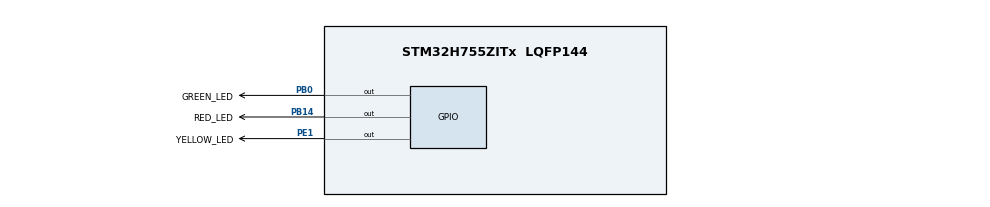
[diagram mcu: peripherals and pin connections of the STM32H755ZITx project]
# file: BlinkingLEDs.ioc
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CortexM4.IPs=BDMA,CORTEX_M4\:I,DEBUG,DMA,FATFS_M4\:I,FREERTOS_M4\:I,GPIO,IWDG2\:I,MDMA,NVIC2\:I,OPENAMP_M4\:I,PDM2PCM_M4\:I,PWR,RCC,RESMGR_UTILITY,SYS_M4\:I,USB_DEVICE_M4\:I,USB_HOST_M4\:I,VREFBUF,WWDG2\:I
CortexM4.Pins=PE1
CortexM7.IPs=BDMA\:I,CORTEX_M7\:I,DEBUG\:I,DMA\:I,FATFS_M7\:I,FREERTOS_M7\:I,GPIO\:I,IWDG1\:I,MDMA\:I,NVIC1\:I,OPENAMP_M7\:I,PDM2PCM_M7\:I,PWR\:I,RCC\:I,RESMGR_UTILITY\:I,SYS\:I,USB_DEVICE_M7\:I,USB_HOST_M7\:I,VREFBUF\:I,WWDG1\:I
CortexM7.Pins=PB0,PB14
Mcu.Family=STM32H7
Mcu.Name=STM32H755ZITx
Mcu.Package=LQFP144
NVIC1.PriorityGroup=NVIC_PRIORITYGROUP_4
NVIC2.PriorityGroup=NVIC_PRIORITYGROUP_4
PA13\ (JTMS/SWDIO).Mode=Serial_Wire
PA13\ (JTMS/SWDIO).PinAttribute=CortexM7
PA13\ (JTMS/SWDIO).Signal=DEBUG_JTMS-SWDIO
PA14\ (JTCK/SWCLK).Mode=Serial_Wire
PA14\ (JTCK/SWCLK).PinAttribute=CortexM7
PA14\ (JTCK/SWCLK).Signal=DEBUG_JTCK-SWCLK
PB0.GPIO_Label=GREEN_LED
PB0.PinAttribute=CortexM7
PB0.Signal=GPIO_Output
PB14.GPIO_Label=RED_LED
PB14.PinAttribute=CortexM7
PB14.Signal=GPIO_Output
PE1.GPIO_Label=YELLOW_LED
PE1.PinAttribute=CortexM4
PE1.Signal=GPIO_Output
ProjectManager.HeapSize=M4-0x200,M7-0x200
ProjectManager.StackSize=M4-0x400,M7-0x400
ProjectManager.TargetToolchain=STM32CubeIDE
RCC.ADCFreq_Value=129000000
RCC.APB1Freq_Value=120000000
RCC.APB2Freq_Value=120000000
RCC.APB3Freq_Value=120000000
RCC.APB4Freq_Value=120000000
RCC.CortexFreq_Value=480000000
RCC.D1PPRE=RCC_APB3_DIV2
RCC.D2PPRE1=RCC_APB1_DIV2
RCC.D2PPRE2=RCC_APB2_DIV2
RCC.D3PPRE=RCC_APB4_DIV2
RCC.DIVM1=4
RCC.DIVN1=60
RCC.HCLKFreq_Value=240000000
RCC.HPRE=RCC_HCLK_DIV2
RCC.PLL2FRACN=0
RCC.PLL3FRACN=0
RCC.PLLFRACN=0
RCC.PWR_Regulator_Voltage_Scale=PWR_REGULATOR_VOLTAGE_SCALE0
RCC.SYSCLKFreq_VALUE=480000000
RCC.SYSCLKSource=RCC_SYSCLKSOURCE_PLLCLK
RCC.USBFreq_Value=480000000
SYS.userName=SYS_M7
VP_SYS_M4_VS_Systick.Mode=SysTick
board=custom

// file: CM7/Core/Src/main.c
/* USER CODE BEGIN Header */
/**
 ******************************************************************************
 * @file           : main.c
 * @brief          : Main program body
 ******************************************************************************
 * @attention
 *
 * Copyright (c) 2023 STMicroelectronics.
 * All rights reserved.
 *
 * This software is licensed under terms that can be found in the LICENSE file
 * in the root directory of this software component.
 * If no LICENSE file comes with this software, it is provided AS-IS.
 *
 ******************************************************************************
 */
/* USER CODE END Header */
#include "main.h"
#include "gpio.h"

/* USER CODE BEGIN PD */

#ifndef HSEM_ID_0
#define HSEM_ID_0 (0U) /* HW semaphore 0*/
#endif

/* USER CODE END PD */

void SystemClock_Config(void);

int main(void)
{
/* USER CODE BEGIN Boot_Mode_Sequence_0 */
	int32_t timeout;
/* USER CODE END Boot_Mode_Sequence_0 */

/* USER CODE BEGIN Boot_Mode_Sequence_1 */
	/* Wait until CPU2 boots and enters in stop mode or timeout*/
	timeout = 0xFFFF;
	while ((__HAL_RCC_GET_FLAG(RCC_FLAG_D2CKRDY) != RESET) && (timeout-- > 0))
		;
	if (timeout < 0)
	{
		Error_Handler();
	}
/* USER CODE END Boot_Mode_Sequence_1 */
  /* MCU Configuration--------------------------------------------------------*/

  /* Reset of all peripherals, Initializes the Flash interface and the Systick. */
  HAL_Init();

  /* Configure the system clock */
  SystemClock_Config();
/* USER CODE BEGIN Boot_Mode_Sequence_2 */
	/* When system initialization is finished, Cortex-M7 will release Cortex-M4 by means of
	 HSEM notification */
	/*HW semaphore Clock enable*/
	__HAL_RCC_HSEM_CLK_ENABLE();
	/*Take HSEM */
	HAL_HSEM_FastTake(HSEM_ID_0);
	/*Release HSEM in order to notify the CPU2(CM4)*/
	HAL_HSEM_Release(HSEM_ID_0, 0);
	/* wait until CPU2 wakes up from stop mode */
	timeout = 0xFFFF;
	while ((__HAL_RCC_GET_FLAG(RCC_FLAG_D2CKRDY) == RESET) && (timeout-- > 0))
		;
	if (timeout < 0)
	{
		Error_Handler();
	}
/* USER CODE END Boot_Mode_Sequence_2 */

  /* Initialize all configured peripherals */
  MX_GPIO_Init();

  /* Infinite loop */
  /* USER CODE BEGIN WHILE */
	while (1)
	{
		HAL_GPIO_TogglePin(GREEN_LED_GPIO_Port, GREEN_LED_Pin);
		HAL_GPIO_TogglePin(RED_LED_GPIO_Port, RED_LED_Pin);

		HAL_Delay(500);
    /* USER CODE END WHILE */

	}
}

void SystemClock_Config(void)
{
  RCC_OscInitTypeDef RCC_OscInitStruct = {0};
  RCC_ClkInitTypeDef RCC_ClkInitStruct = {0};

  /** Supply configuration update enable
  */
  HAL_PWREx_ConfigSupply(PWR_LDO_SUPPLY);

  /** Configure the main internal regulator output voltage
  */
  __HAL_PWR_VOLTAGESCALING_CONFIG(PWR_REGULATOR_VOLTAGE_SCALE1);

  while(!__HAL_PWR_GET_FLAG(PWR_FLAG_VOSRDY)) {}

  __HAL_RCC_SYSCFG_CLK_ENABLE();
  __HAL_PWR_VOLTAGESCALING_CONFIG(PWR_REGULATOR_VOLTAGE_SCALE0);

  while(!__HAL_PWR_GET_FLAG(PWR_FLAG_VOSRDY)) {}

  /** Initializes the RCC Oscillators according to the specified parameters
  * in the RCC_OscInitTypeDef structure.
  */
  RCC_OscInitStruct.OscillatorType = RCC_OSCILLATORTYPE_HSI;
  RCC_OscInitStruct.HSIState = RCC_HSI_DIV1;
  RCC_OscInitStruct.HSICalibrationValue = RCC_HSICALIBRATION_DEFAULT;
  RCC_OscInitStruct.PLL.PLLState = RCC_PLL_ON;
  RCC_OscInitStruct.PLL.PLLSource = RCC_PLLSOURCE_HSI;
  RCC_OscInitStruct.PLL.PLLM = 4;
  RCC_OscInitStruct.PLL.PLLN = 60;
  RCC_OscInitStruct.PLL.PLLP = 2;
  RCC_OscInitStruct.PLL.PLLQ = 2;
  RCC_OscInitStruct.PLL.PLLR = 2;
  RCC_OscInitStruct.PLL.PLLRGE = RCC_PLL1VCIRANGE_3;
  RCC_OscInitStruct.PLL.PLLVCOSEL = RCC_PLL1VCOWIDE;
  RCC_OscInitStruct.PLL.PLLFRACN = 0;
  if (HAL_RCC_OscConfig(&RCC_OscInitStruct) != HAL_OK)
  {
    Error_Handler();
  }

  /** Initializes the CPU, AHB and APB buses clocks
  */
  RCC_ClkInitStruct.ClockType = RCC_CLOCKTYPE_HCLK|RCC_CLOCKTYPE_SYSCLK
                              |RCC_CLOCKTYPE_PCLK1|RCC_CLOCKTYPE_PCLK2
                              |RCC_CLOCKTYPE_D3PCLK1|RCC_CLOCKTYPE_D1PCLK1;
  RCC_ClkInitStruct.SYSCLKSource = RCC_SYSCLKSOURCE_PLLCLK;
  RCC_ClkInitStruct.SYSCLKDivider = RCC_SYSCLK_DIV1;
  RCC_ClkInitStruct.AHBCLKDivider = RCC_HCLK_DIV2;
  RCC_ClkInitStruct.APB3CLKDivider = RCC_APB3_DIV2;
  RCC_ClkInitStruct.APB1CLKDivider = RCC_APB1_DIV2;
  RCC_ClkInitStruct.APB2CLKDivider = RCC_APB2_DIV2;
  RCC_ClkInitStruct.APB4CLKDivider = RCC_APB4_DIV2;

  if (HAL_RCC_ClockConfig(&RCC_ClkInitStruct, FLASH_LATENCY_4) != HAL_OK)
  {
    Error_Handler();
  }
}

void Error_Handler(void)
{
	__disable_irq();
	while (1)
	{
	}
}
